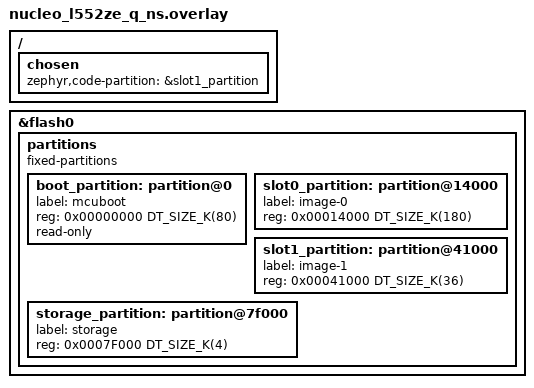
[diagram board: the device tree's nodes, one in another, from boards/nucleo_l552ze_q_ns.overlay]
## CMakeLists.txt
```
# SPDX-License-Identifier: Apache-2.0

cmake_minimum_required(VERSION 3.28.0)

find_package(Zephyr REQUIRED HINTS $ENV{ZEPHYR_BASE})

project(tfm_ipc)

target_sources(app PRIVATE src/main.c)

target_include_directories(app PRIVATE
  $<TARGET_PROPERTY:tfm,TFM_BINARY_DIR>/api_ns/interface/include
)
```

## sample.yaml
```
sample:
  description: This app provides an example of using TF-M on the secure side, with
    Zephyr on the NS side, using IPC.
  name: TF-M IPC example
common:
  tags:
    - trusted-firmware-m
    - mcuboot
  integration_platforms:
    - mps2/an521/cpu0/ns
  harness: console
  harness_config:
    type: multi_line
    regex:
      - "TF-M IPC on .*"
      - "The version of the PSA Framework API is"
      - "The PSA Crypto service minor version is"
      - "Generating 256 bytes of random data"
tests:
  sample.tfm.tfm_ipc.no_bl2:
    tags:
      - trusted-firmware-m
    platform_allow:
      - mps2/an521/cpu0/ns
      - nrf54l15dk/nrf54l15/cpuapp/ns
      - nrf54l15dk/nrf54l10/cpuapp/ns
      - nrf54lm20dk/nrf54lm20a/cpuapp/ns
      - nrf54lm20dk/nrf54lm20b/cpuapp/ns
      - nrf7120dk/nrf7120/cpuapp/ns
    extra_configs:
      - CONFIG_TFM_BL2=n
  sample.tfm.tfm_ipc.bl2.rsa2048:
    platform_allow:
      - mps2/an521/cpu0/ns
    extra_configs:
      - CONFIG_TFM_MCUBOOT_SIGNATURE_TYPE="RSA-2048"
  sample.tfm.tfm_ipc.bl2.rsa3072:
    platform_allow:
      - mps2/an521/cpu0/ns
      - b_u585i_iot02a/stm32u585xx/ns
      - stm32h573i_dk/stm32h573xx/ns
    extra_configs:
      - CONFIG_TFM_MCUBOOT_SIGNATURE_TYPE="RSA-3072"
  sample.tfm.tfm_ipc.bl2.ecp256:
    platform_allow:
      - mps2/an521/cpu0/ns
      - nrf5340dk/nrf5340/cpuapp/ns
      - nrf9160dk/nrf9160/ns
      - nucleo_l552ze_q/stm32l552xx/ns
      - stm32l562e_dk/stm32l562xx/ns
      - v2m_musca_s1/musca_s1/ns
      - bl5340_dvk/nrf5340/cpuapp/ns
      - frdm_mcxn947/mcxn947/cpu0/ns
      - frdm_mcxa577/mcxa577/ns
    extra_configs:
      - CONFIG_TFM_MCUBOOT_SIGNATURE_TYPE="EC-P256"
  sample.tfm.tfm_ipc.bl2.ecp384:
    platform_allow:
      - mps2/an521/cpu0/ns
    extra_configs:
      - CONFIG_TFM_MCUBOOT_SIGNATURE_TYPE="EC-P384"
```

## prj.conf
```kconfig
CONFIG_PSA_CRYPTO=y
CONFIG_TFM_IPC=y
CONFIG_REBOOT=y

# The Zephyr CMSIS emulation assumes that ticks are ms, currently
CONFIG_SYS_CLOCK_TICKS_PER_SEC=1000

CONFIG_MAIN_STACK_SIZE=4096
CONFIG_HEAP_MEM_POOL_SIZE=4096
```

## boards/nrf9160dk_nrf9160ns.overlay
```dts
/*
 * Copyright (c) 2019-2020 Nordic Semiconductor ASA
 *
 * SPDX-License-Identifier: Apache-2.0
 */

&uart1 {
	status = "disabled";
};

&sram0_s {
	reg = <0x20000000 DT_SIZE_K(88)>;
};

/delete-node/ &sram0_bsd;
/delete-node/ &sram0_ns;
/ {
	reserved-memory {
		sram0_ns: image_ns@20016000 {
			reg = <0x20016000 DT_SIZE_K(168)>;
		};
	};
};
```

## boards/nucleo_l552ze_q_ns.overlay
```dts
/*
 * Copyright (c) 2020 Linaro Limited.
 *
 * SPDX-License-Identifier: Apache-2.0
 */


 /* This partition table should be used along with TFM configuration:
  * - TEST_S=OFF (NO REGRESSION)
  * - TFM_PSA_API=ON (IPC)
  *
  * In this configuration, TFM binary does not include tests.
  * The partition sizes are compatible with the TF-M platform
  * flash_layout.h.
  */

/ {
	chosen {
		zephyr,code-partition = &slot1_partition;
	};
};

&flash0 {

	partitions {
		compatible = "fixed-partitions";
		#address-cells = <1>;
		#size-cells = <1>;

		boot_partition: partition@0 {
			label = "mcuboot";
			reg = <0x00000000 DT_SIZE_K(80)>;
			read-only;
		};
		/* Secure image primary slot */
		slot0_partition: partition@14000 {
			label = "image-0";
			reg = <0x00014000 DT_SIZE_K(180)>;
		};
		/* Non-secure image primary slot */
		slot1_partition: partition@41000 {
			label = "image-1";
			reg = <0x00041000 DT_SIZE_K(36)>;
		};
		/*
		 * The flash starting at 0x7F000 and ending at
		 * 0x80000 is reserved for the application.
		 */
		storage_partition: partition@7f000 {
			label = "storage";
			reg = <0x0007F000 DT_SIZE_K(4)>;
		};
	};
};
```

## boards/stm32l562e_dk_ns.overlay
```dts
/*
 * Copyright (c) 2021 Yestin Sun
 *
 * SPDX-License-Identifier: Apache-2.0
 */

 /* This partition table should be used along with TFM configuration:
  * - TEST_S=OFF (NO REGRESSION)
  * - TFM_PSA_API=ON (IPC)
  *
  * In this configuration, TFM binary does not include tests.
  * The partition sizes are compatible with the TF-M platform
  * flash_layout.h.
  */

/ {
	chosen {
		zephyr,code-partition = &slot1_partition;
	};
};

&flash0 {

	partitions {
		compatible = "fixed-partitions";
		#address-cells = <1>;
		#size-cells = <1>;

		boot_partition: partition@0 {
			label = "mcuboot";
			reg = <0x00000000 0x00019000>;
			read-only;
		};
		/* Secure image primary slot */
		slot0_partition: partition@19000 {
			label = "image-0";
			reg = <0x00019000 0x00038000>;
		};
		/* Non-secure image primary slot */
		slot1_partition: partition@51000 {
			label = "image-1";
			reg = <0x00051000 0x0002A000>;
		};
		/*
		 * The flash starting at 0x7F000 and ending at
		 * 0x80000 is reserved for the application.
		 */
		storage_partition: partition@7f000 {
			label = "storage";
			reg = <0x0007F000 0x00001000>;
		};
	};
};
```

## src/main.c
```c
/*
 * Copyright (c) 2019,2020, 2021, 2023 Linaro Limited
 *
 * SPDX-License-Identifier: Apache-2.0
 */

#include <zephyr/kernel.h>
#include <zephyr/sys/printk.h>

#include <tfm_ns_interface.h>
#ifdef TFM_PSA_API
#include <psa_manifest/sid.h>
#include <psa/crypto.h>
#endif

/**
 * \brief Retrieve the version of the PSA Framework API.
 *
 * \note This is a functional test only and doesn't
 *       mean to test all possible combinations of
 *       input parameters and return values.
 */
static void tfm_get_version(void)
{
	uint32_t version;

	version = psa_framework_version();
	if (version == PSA_FRAMEWORK_VERSION) {
		printk("The version of the PSA Framework API is %d.\n",
		       version);
	} else {
		printk("The version of the PSA Framework API is not valid!\n");
		return;
	}
}

#ifdef TFM_PSA_API
/**
 * \brief Retrieve the minor version of a RoT Service.
 */
static void tfm_get_sid(void)
{
	uint32_t version;

	version = psa_version(TFM_CRYPTO_SID);
	if (version == PSA_VERSION_NONE) {
		printk("RoT Service is not implemented or caller is not ");
		printk("authorized to access it!\n");
		return;
	}

	/* Valid version number */
	printk("The PSA Crypto service minor version is %d.\n", version);
}

/**
 * \brief Generates random data using the TF-M crypto service.
 */
void tfm_psa_crypto_rng(void)
{
	psa_status_t status;
	uint8_t outbuf[256] = { 0 };

	status = psa_generate_random(outbuf, 256);
	printk("Generating 256 bytes of random data:");
	for (uint16_t i = 0; i < 256; i++) {
		if (!(i % 16)) {
			printk("\n");
		}
		printk("%02X ", (uint8_t)(outbuf[i] & 0xFF));
	}
	printk("\n");
}
#endif

int main(void)
{
	printk("TF-M IPC on %s\n", CONFIG_BOARD);

	tfm_get_version();
#ifdef TFM_PSA_API
	tfm_get_sid();
	tfm_psa_crypto_rng();
#endif
	return 0;
}
```
